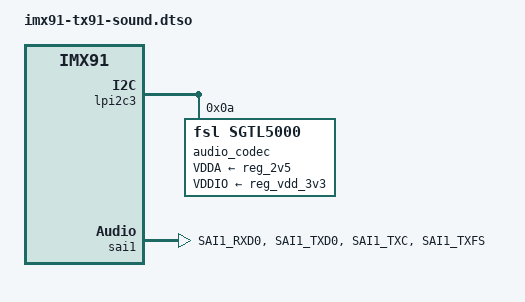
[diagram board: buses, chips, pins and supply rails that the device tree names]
// SPDX-License-Identifier: (GPL-2.0 OR MIT)
/*
 * Copyright 2023 Lothar Waßmann <LW@KARO-electronics.de>
 *
 */

/dts-v1/;
/plugin/;

#include "includes/imx91-karo-sound.dtsi"
#include "imx91-pinfunc.h"

&{/chosen} {
	overlays {
		tx91-sound;
	};
};

&cpu_dai {
	sound-dai = <&sai1>;
};

&lpi2c3 {
	status = "okay";

	audio_codec: codec@a {
		compatible = "fsl,sgtl5000";
		reg = <0xa>;
		#sound-dai-cells = <0>;
		VDDA-supply = <&reg_2v5>;
		VDDIO-supply = <&reg_vdd_3v3>;
		clocks = <&audio_clk>;
	};
};

&sai1 {
	pinctrl-names = "default";
	pinctrl-0 = <&pinctrl_sai1>;
	#sound-dai-cells = <0>;
	status = "okay";
};

&iomuxc {
	pinctrl_sai1: sai1grp {
		fsl,pins = <
			MX91_PAD_SAI1_RXD0__SAI1_RX_DATA0		0x131e
			MX91_PAD_SAI1_TXD0__SAI1_TX_DATA0		0x131e
			MX91_PAD_SAI1_TXC__SAI1_TX_BCLK			0x131e
			MX91_PAD_SAI1_TXFS__SAI1_TX_SYNC		0x131e
		>;
	};
};
